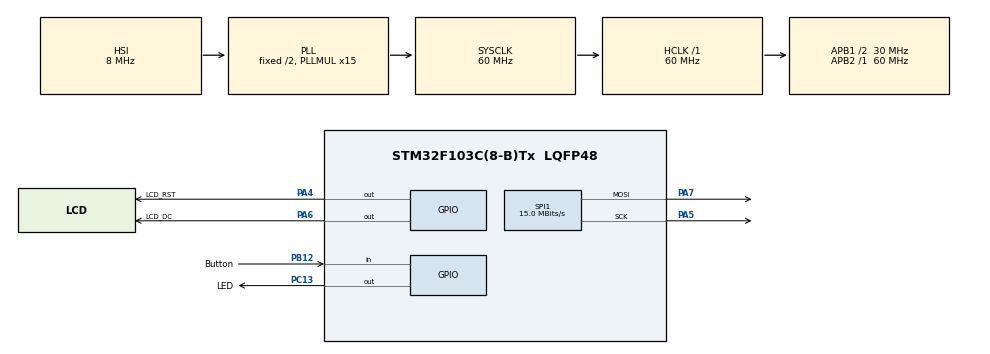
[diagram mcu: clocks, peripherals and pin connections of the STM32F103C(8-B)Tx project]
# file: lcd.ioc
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Mcu.Family=STM32F1
Mcu.Name=STM32F103C(8-B)Tx
Mcu.Package=LQFP48
NVIC.PriorityGroup=NVIC_PRIORITYGROUP_4
NVIC.TIM2_IRQn=true\:0\:0\:false\:false\:true\:true\:true\:true
PA13.Mode=Serial_Wire
PA13.Signal=SYS_JTMS-SWDIO
PA14.Mode=Serial_Wire
PA14.Signal=SYS_JTCK-SWCLK
PA4.GPIO_Label=LCD_RST
PA4.Signal=GPIO_Output
PA5.Mode=TX_Only_Simplex_Unidirect_Master
PA5.Signal=SPI1_SCK
PA6.GPIO_Label=LCD_DC
PA6.GPIO_Speed=GPIO_SPEED_FREQ_HIGH
PA6.Signal=GPIO_Output
PA7.Mode=TX_Only_Simplex_Unidirect_Master
PA7.Signal=SPI1_MOSI
PB12.GPIO_Label=Button
PB12.GPIO_PuPd=GPIO_PULLUP
PB12.Signal=GPIO_Input
PC13-TAMPER-RTC.GPIO_Label=LED
PC13-TAMPER-RTC.Signal=GPIO_Output
ProjectManager.HeapSize=0x200
ProjectManager.StackSize=0x400
ProjectManager.TargetToolchain=CMake
RCC.AHBFreq_Value=60000000
RCC.APB1CLKDivider=RCC_HCLK_DIV2
RCC.APB1Freq_Value=30000000
RCC.APB1TimFreq_Value=60000000
RCC.APB2Freq_Value=60000000
RCC.APB2TimFreq_Value=60000000
RCC.HCLKFreq_Value=60000000
RCC.PLLMUL=RCC_PLL_MUL15
RCC.SYSCLKFreq_VALUE=60000000
RCC.SYSCLKSource=RCC_SYSCLKSOURCE_PLLCLK
RCC.USBFreq_Value=60000000
SPI1.BaudRatePrescaler=SPI_BAUDRATEPRESCALER_4
SPI1.CalculateBaudRate=15.0 MBits/s
SPI1.Direction=SPI_DIRECTION_2LINES
SPI1.Mode=SPI_MODE_MASTER
SPI1.VirtualType=VM_MASTER
TIM2.AutoReloadPreload=TIM_AUTORELOAD_PRELOAD_ENABLE
TIM2.CounterMode=TIM_COUNTERMODE_UP
TIM2.Period=999
TIM2.Prescaler=699
VP_TIM2_VS_ClockSourceINT.Mode=Internal
board=custom

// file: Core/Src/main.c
/* USER CODE BEGIN Header */
/**
  ******************************************************************************
  * @file           : main.c
  * @brief          : Main program body
  ******************************************************************************
  * @attention
  *
  * Copyright (c) 2024 STMicroelectronics.
  * All rights reserved.
  *
  * This software is licensed under terms that can be found in the LICENSE file
  * in the root directory of this software component.
  * If no LICENSE file comes with this software, it is provided AS-IS.
  *
  ******************************************************************************
  */
/* USER CODE END Header */
#include "main.h"
#include "spi.h"
#include "tim.h"
#include "gpio.h"

void SystemClock_Config(void);

int main(void)
{

  /* MCU Configuration--------------------------------------------------------*/

  /* Reset of all peripherals, Initializes the Flash interface and the Systick. */
  HAL_Init();

  /* Configure the system clock */
  SystemClock_Config();

  /* Initialize all configured peripherals */
  MX_GPIO_Init();
  MX_TIM2_Init();
  MX_SPI1_Init();

  /* Infinite loop */
  /* USER CODE BEGIN WHILE */
  // while (1)
  {
    extern void app_main(void);
    app_main();
    /* USER CODE END WHILE */

  }
}

void SystemClock_Config(void)
{
  RCC_OscInitTypeDef RCC_OscInitStruct = {0};
  RCC_ClkInitTypeDef RCC_ClkInitStruct = {0};

  /** Initializes the RCC Oscillators according to the specified parameters
  * in the RCC_OscInitTypeDef structure.
  */
  RCC_OscInitStruct.OscillatorType = RCC_OSCILLATORTYPE_HSI;
  RCC_OscInitStruct.HSIState = RCC_HSI_ON;
  RCC_OscInitStruct.HSICalibrationValue = RCC_HSICALIBRATION_DEFAULT;
  RCC_OscInitStruct.PLL.PLLState = RCC_PLL_ON;
  RCC_OscInitStruct.PLL.PLLSource = RCC_PLLSOURCE_HSI_DIV2;
  RCC_OscInitStruct.PLL.PLLMUL = RCC_PLL_MUL15;
  if (HAL_RCC_OscConfig(&RCC_OscInitStruct) != HAL_OK)
  {
    Error_Handler();
  }

  /** Initializes the CPU, AHB and APB buses clocks
  */
  RCC_ClkInitStruct.ClockType = RCC_CLOCKTYPE_HCLK|RCC_CLOCKTYPE_SYSCLK
                              |RCC_CLOCKTYPE_PCLK1|RCC_CLOCKTYPE_PCLK2;
  RCC_ClkInitStruct.SYSCLKSource = RCC_SYSCLKSOURCE_PLLCLK;
  RCC_ClkInitStruct.AHBCLKDivider = RCC_SYSCLK_DIV1;
  RCC_ClkInitStruct.APB1CLKDivider = RCC_HCLK_DIV2;
  RCC_ClkInitStruct.APB2CLKDivider = RCC_HCLK_DIV1;

  if (HAL_RCC_ClockConfig(&RCC_ClkInitStruct, FLASH_LATENCY_2) != HAL_OK)
  {
    Error_Handler();
  }
}

void Error_Handler(void)
{
  __disable_irq();
  while (1)
  {
  }
}
